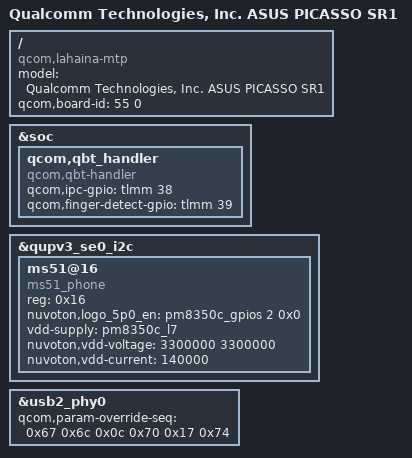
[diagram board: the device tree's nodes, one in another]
/dts-v1/;
/plugin/;

#include "PICASSO-EVB2-overlay.dts"


/ {
	model = "Qualcomm Technologies, Inc. ASUS PICASSO SR1";
	compatible = "qcom,lahaina-mtp", "qcom,lahaina", "qcom,mtp";
	qcom,board-id = <55 0>;
};

/*   ====================================
*    overlay for display - start
*    ====================================
*/

/*   ====================================
*    overlay for display - end
*    ====================================
*/

/*    ====================================
 *    overlay for lahainap-v2.dtsi - start
 *    ====================================
 */

/*    ====================================
 *    overlay for lahainap-v2.dtsi - end
 *    ====================================
 */



/*    ====================================
 *    overlay for lahainap.dtsi - start
 *    ====================================
 */

/*    ====================================
 *    overlay for lahainap.dtsi - end
 *    ====================================
 */



/*    ====================================
 *    overlay for lahaina-mtp.dtsi - start
 *    ====================================
 */
 
&soc {
	qcom,qbt_handler {
		compatible = "qcom,qbt-handler";
		qcom,ipc-gpio = <&tlmm 38 0>;
		qcom,finger-detect-gpio = <&tlmm 39 0>;
	};
}; 

&qupv3_se0_i2c {
	status = "ok";

	ms51@16 {
		compatible = "ms51_phone";
		reg = <0x16>;

		//panel = <&dsi_r66451_fhd_video &dsi_r66451_fhd_dsc_cmd_dim>;
		nuvoton,logo_5p0_en = <&pm8350c_gpios 2 0x0>;

		vdd-supply = <&pm8350c_l7>;
		nuvoton,vdd-voltage = <3300000 3300000>;
		nuvoton,vdd-current = <140000>;
	};
};

/*    ====================================
 *    overlay for lahaina-mtp.dtsi - end
 *    ====================================
 */


/*    ====================================
 *    overlay for lahaina-pm.dtsi - start
 *    ====================================
 */

/*    ====================================
 *    overlay for lahaina-pm.dtsi - end
 *    ====================================
 */



/*    ====================================
 *    overlay for lahaina-pinctrl.dtsi - start
 *    ====================================
 */

/*    ====================================
 *    overlay for lahaina-pinctrl.dtsi - end
 *    ====================================
 */



/*    ====================================
 *    overlay for lahaina-pmic-overlay.dtsi - start
 *    ====================================
 */




/*    ====================================
 *    overlay for lahaina-pmic-overlay.dtsi - end
 *    ====================================
 */


/*    ====================================
 *    overlay for pm8350.dtsi - start
 *    ====================================
 */

/*    ====================================
 *    overlay for pm8350.dtsi - end
 *    ====================================
 */


/*    ====================================
 *    overlay for pmk8350.dtsi - start
 *    ====================================
 */

/*    ====================================
 *    overlay for pmk8350.dtsi - end
 *    ====================================
 */

/*    ====================================
 *    overlay for pm8350b.dtsi - start
 *    ====================================
 */

/*    ====================================
 *    overlay for pm8350b.dtsi - end
 *    ====================================
 */

/*    ====================================
 *    overlay for pm8350c.dtsi - start
 *    ====================================
 */

/*    ====================================
 *    overlay for pm8350c.dtsi - end
 *    ====================================
 */


/*    ====================================
 *    overlay for lahaina-regulators.dtsi - start
 *    ====================================
 */

/*    ====================================
 *    overlay for lahaina-regulators.dtsi - end
 *    ====================================
 */
  

 
/*    ====================================
 *    overlay for lahaina-audio.dtsi - start
 *    ====================================
 */

/*    ====================================
 *    overlay for lahaina-audio.dtsi - end
 *    ====================================
 */

/*    ====================================
 *    overlay for lahaina-audio-overlay.dtsi - start
 *    ====================================
 */

/*    ====================================
 *    overlay for lahaina-audio-overlay.dtsi - end
 *    ====================================
 */


/*    ====================================
 *    overlay for lahaina-thermal-overlay.dtsi - start
 *    ====================================
 */

/*    ====================================
 *    overlay for lahaina-thermal-overlay.dtsi - end
 *    ====================================
 */

 
/*    ====================================
 *    overlay for lahaina-gpu.dtsi - start
 *    ====================================
 */

/*    ====================================
 *    overlay for lahaina-gpu.dtsi - end
 *    ====================================
 */


/*    ====================================
 *    overlay for lahaina-usb.dtsi - start
 *    ====================================
 */
&usb2_phy0 {
	qcom,param-override-seq = <0x67 0x6c	/* override_x0 */
				   0x0c 0x70	/* override_x1 */
				   0x17 0x74>;	/* override x2 */
};

/*    ====================================
 *    overlay for lahaina-usb.dtsi - end
 *    ====================================
 */
